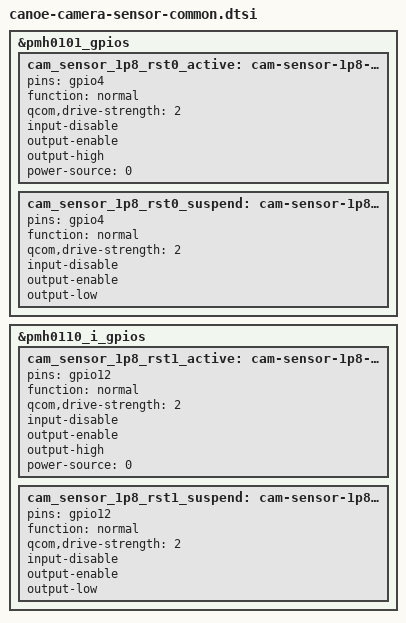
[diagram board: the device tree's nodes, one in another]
// SPDX-License-Identifier: BSD-3-Clause
/*
* Copyright (c) Qualcomm Technologies, Inc. and/or its subsidiaries.
*/

&pmh0101_gpios {
	cam_sensor_1p8_rst0_active: cam-sensor-1p8-rst0-active-state {
		pins = "gpio4";
		function = "normal";
		qcom,drive-strength = <2>;
		input-disable;
		output-enable;
		output-high;
		power-source = <0>; /* 1.8 V */
	};

	cam_sensor_1p8_rst0_suspend: cam-sensor-1p8-rst0-suspend-state {
		pins = "gpio4";
		function = "normal";
		qcom,drive-strength = <2>;
		input-disable;
		output-enable;
		output-low;
	};
};

&pmh0110_i_gpios {
	cam_sensor_1p8_rst1_active: cam-sensor-1p8-rst1-active-state {
		pins = "gpio12";
		function = "normal";
		qcom,drive-strength = <2>;
		input-disable;
		output-enable;
		output-high;
		power-source = <0>; /* 1.8 V */
	};

	cam_sensor_1p8_rst1_suspend: cam-sensor-1p8-rst1-suspend-state {
		pins = "gpio12";
		function = "normal";
		qcom,drive-strength = <2>;
		input-disable;
		output-enable;
		output-low;
	};
};
